# MK20D10 register map
Vendor: Freescale Semiconductor, Inc.; Series: Kinetis_K; File version: 1.6
CPU: CM4 r0p1, little endian, no MPU, no FPU, VTOR, 4 interrupt priority bits
Registers are 32-bit, read-write, reset 0x0 unless marked. A register's access mark holds for its fields unless they carry their own. Offsets are from the block's base; [hi:lo] are bit positions; {n}, {i} and the like mark numbered series; 'fields as' and 'values as' point back to an identical list.

## MPU — Memory protection unit
Base 0x4000D000; register names take the prefix MPU_
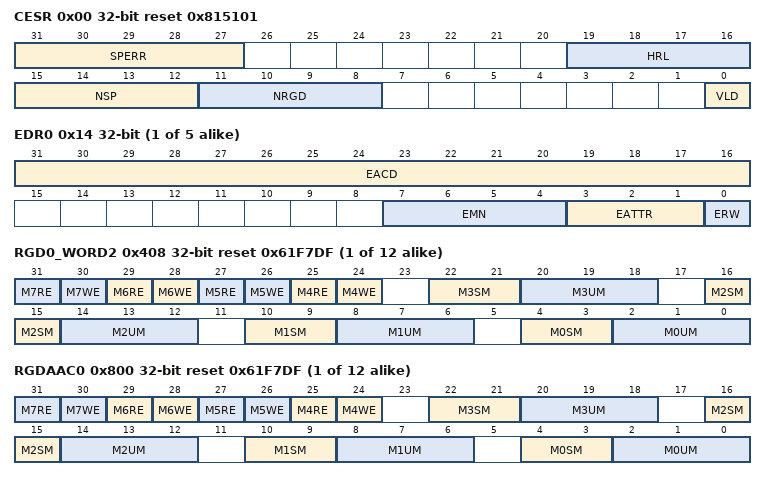
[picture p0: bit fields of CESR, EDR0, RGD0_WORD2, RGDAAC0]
0x00 CESR reset 0x815101 — Control/Error Status Register
  [31:27] SPERR — Slave Port n Error
    0=No error has occurred for slave port n; 1=An error has occurred for slave port n
  [19:16] HRL ro — Hardware Revision Level
  [15:12] NSP ro — Number Of Slave Ports
  [11:8] NRGD ro — Number Of Region Descriptors
    0=8 region descriptors; 1=12 region descriptors; 2=16 region descriptors
  [0] VLD — Valid
    0=MPU is disabled. All accesses from all bus masters are allowed.; 1=MPU is enabled
{0x10+8i} EAR{i} (i=0..4) ro reset not defined — Error Address Register, slave port n
  [31:0] EADDR — Error Address
{0x14+8i} EDR{i} (i=0..4) ro reset not defined — Error Detail Register, slave port n
  [31:16] EACD — Error Access Control Detail
  [7:4] EMN — Error Master Number
  [3:1] EATTR — Error Attributes
    0=User mode, instruction access; 1=User mode, data access; 2=Supervisor mode, instruction access; 3=Supervisor mode, data access
  [0] ERW — Error Read/Write
    0=Read; 1=Write
{0x400+0x10*i} RGD{i}_WORD0 (i=0..11) — Region Descriptor n, Word 0
  [31:5] SRTADDR — Start Address
{0x404+0x10*i} RGD{i}_WORD1 (i=0..11) reset 0xFFFFFFFF — Region Descriptor n, Word 1
  [31:5] ENDADDR — End Address
{0x408+0x10*i} RGD{i}_WORD2 (i=0..11) reset 0x61F7DF — Region Descriptor n, Word 2
  [2n+17] M{n}RE (n=4..7) — Bus Master {n} Read Enable
    0=Bus master {n} reads terminate with an access error and the read is not performed; 1=Bus master {n} reads allowed
  [2n+16] M{n}WE (n=4..7) — Bus Master {n} Write Enable
    0=Bus master {n} writes terminate with an access error and the write is not performed; 1=Bus master {n} writes allowed
  [22:21] M3SM — Bus Master 3 Supervisor Mode Access Control
    0=r/w/x; read, write and execute allowed; 1=r/x; read and execute allowed, but no write; 2=r/w; read and write allowed, but no execute; 3=Same as User mode defined in M3UM
  [20:18] M3UM — Bus Master 3 User Mode Access Control
    0=An attempted access of that mode may be terminated with an access error (if not allowed by another descriptor) and the access not performed; 1=Allows the given access type to occur
  [16:15] M2SM — Bus Master 2 Supervisor Mode Access Control
  [14:12] M2UM — Bus Master 2 User Mode Access control
  [10:9] M1SM — Bus Master 1 Supervisor Mode Access Control
  [8:6] M1UM — Bus Master 1 User Mode Access Control
  [4:3] M0SM — Bus Master 0 Supervisor Mode Access Control
  [2:0] M0UM — Bus Master 0 User Mode Access Control
{0x40C+0x10*i} RGD{i}_WORD3 (i=0..11) reset 0x1 — Region Descriptor n, Word 3
  [0] VLD — Valid
    0=Region descriptor is invalid; 1=Region descriptor is valid
{0x800+4i} RGDAAC{i} (i=0..11) reset 0x61F7DF — Region Descriptor Alternate Access Control n
  [2n+17] M{n}RE (n=4..7) — Bus Master {n} Read Enable
    values as RGD0_WORD2.M4RE
  [2n+16] M{n}WE (n=4..7) — Bus Master {n} Write Enable
    values as RGD0_WORD2.M4WE
  [22:21] M3SM — Bus Master 3 Supervisor Mode Access Control
    values as RGD0_WORD2.M3SM
  [20:18] M3UM — Bus Master 3 User Mode Access Control
    values as RGD0_WORD2.M3UM
  [16:15] M2SM — Bus Master 2 Supervisor Mode Access Control
  [14:12] M2UM — Bus Master 2 User Mode Access Control
  [10:9] M1SM — Bus Master 1 Supervisor Mode Access Control
  [8:6] M1UM — Bus Master 1 User Mode Access Control
  [4:3] M0SM — Bus Master 0 Supervisor Mode Access Control
  [2:0] M0UM — Bus Master 0 User Mode Access Control

## DMAMUX — DMA channel multiplexor
Base 0x40021000; register names take the prefix DMAMUX_
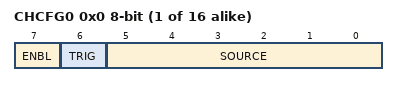
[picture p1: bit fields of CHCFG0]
{0x0+i} CHCFG{i} (i=0..15) 8-bit — Channel Configuration register
  [7] ENBL — DMA Channel Enable
    0=DMA channel is disabled. This mode is primarily used during configuration of the DMA Mux. The DMA has separate channel enables/disables, which should be used to disable or re-configure a DMA channel.; 1=DMA channel is enabled
  [6] TRIG — DMA Channel Trigger Enable
    0=Triggering is disabled. If triggering is disabled, and the ENBL bit is set, the DMA Channel will simply route the specified source to the DMA channel. (Normal mode); 1=Triggering is enabled. If triggering is enabled, and the ENBL bit is set, the DMAMUX is in Periodic Trigger mode.
  [5:0] SOURCE — DMA Channel Source (Slot)

## Notices in the file
Redistribution and use in source and binary forms, with or without modification,
are permitted provided that the following conditions are met:
o Redistributions of source code must retain the above copyright notice, this list
of conditions and the following disclaimer.
o Redistributions in binary form must reproduce the above copyright notice, this
list of conditions and the following disclaimer in the documentation and/or
other materials provided with the distribution.
o Neither the name of Freescale Semiconductor, Inc. nor the names of its
contributors may be used to endorse or promote products derived from this
software without specific prior written permission.
THIS SOFTWARE IS PROVIDED BY THE COPYRIGHT HOLDERS AND CONTRIBUTORS "AS IS" AND
ANY EXPRESS OR IMPLIED WARRANTIES, INCLUDING, BUT NOT LIMITED TO, THE IMPLIED
WARRANTIES OF MERCHANTABILITY AND FITNESS FOR A PARTICULAR PURPOSE ARE
DISCLAIMED. IN NO EVENT SHALL THE COPYRIGHT HOLDER OR CONTRIBUTORS BE LIABLE FOR
ANY DIRECT, INDIRECT, INCIDENTAL, SPECIAL, EXEMPLARY, OR CONSEQUENTIAL DAMAGES
(INCLUDING, BUT NOT LIMITED TO, PROCUREMENT OF SUBSTITUTE GOODS OR SERVICES;
LOSS OF USE, DATA, OR PROFITS; OR BUSINESS INTERRUPTION) HOWEVER CAUSED AND ON
ANY THEORY OF LIABILITY, WHETHER IN CONTRACT, STRICT LIABILITY, OR TORT
(INCLUDING NEGLIGENCE OR OTHERWISE) ARISING IN ANY WAY OUT OF THE USE OF THIS
SOFTWARE, EVEN IF ADVISED OF THE POSSIBILITY OF SUCH DAMAGE.
